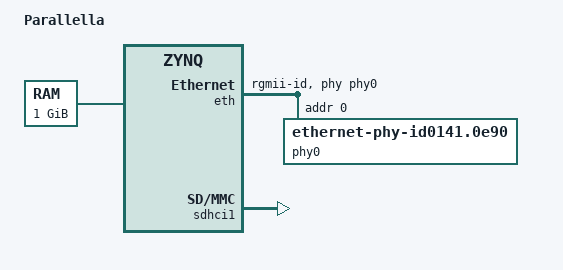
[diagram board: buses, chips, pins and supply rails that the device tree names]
/include/ "zynq.dtsi"

/ {
	model = "Parallella";
	memory {
		device_type = "memory";
		reg = <0x000000000 0x40000000>;
	};

	chosen {
		bootargs = "console=ttyPS0,115200 root=/dev/mmcblk0p2 rw earlyprintk rootfstype=ext4 rootwait";
		linux,stdout-path = "/amba@0/uart@E0001000";
	};
};

&eth {
	phy-handle = <&phy0>;
	phy-mode = "rgmii-id";



	phy0: phy@0 {
 		compatible = "ethernet-phy-id0141.0e90",
                             "ethernet-phy-ieee802.3-c22";
                reg = <0>;
                marvell,reg-init = <0x3 0x10 0xff00 0x1e>,
                                   <0x3 0x11 0xfff0 0xa>;
		device_type = "ethernet-phy";
	};
};

&sdhci0 {
	status = "disabled";
};

&sdhci1 {
        status = "okay";
};
